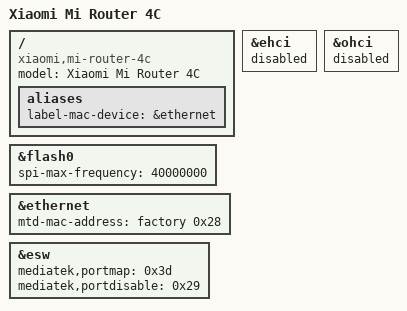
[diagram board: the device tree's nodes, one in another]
// SPDX-License-Identifier: GPL-2.0-or-later OR MIT

#include "mt7628an_xiaomi_mi-router-4.dtsi"

/ {
	compatible = "xiaomi,mi-router-4c", "mediatek,mt7628an-soc";
	model = "Xiaomi Mi Router 4C";

	aliases {
		label-mac-device = &ethernet;
	};
};

&flash0 {
	spi-max-frequency = <40000000>;
};

&ehci {
	status = "disabled";
};

&ohci {
	status = "disabled";
};

&ethernet {
	mtd-mac-address = <&factory 0x28>;
};

&esw {
	mediatek,portmap = <0x3d>;
	mediatek,portdisable = <0x29>;
};
